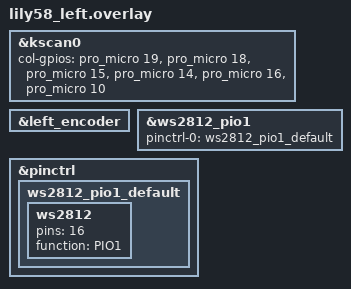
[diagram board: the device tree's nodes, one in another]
#include "lily58.dtsi"

&kscan0 {
    col-gpios
        = <&pro_micro 19 GPIO_ACTIVE_HIGH>
        , <&pro_micro 18 GPIO_ACTIVE_HIGH>
        , <&pro_micro 15 GPIO_ACTIVE_HIGH>
        , <&pro_micro 14 GPIO_ACTIVE_HIGH>
        , <&pro_micro 16 GPIO_ACTIVE_HIGH>
        , <&pro_micro 10 GPIO_ACTIVE_HIGH>
        ;
};

&left_encoder {
    status = "okay";
};

// Configure the PIO for WS2812 on the specific pin
&ws2812_pio1 {
    pinctrl-0 = <&ws2812_pio1_default>;
    pinctrl-names = "default";
};

&pinctrl {
    ws2812_pio1_default: ws2812_pio1_default {
        ws2812 {
            pins = <16>; // Change this to your actual LED data pin
            function = "PIO1";
        };
    };
};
